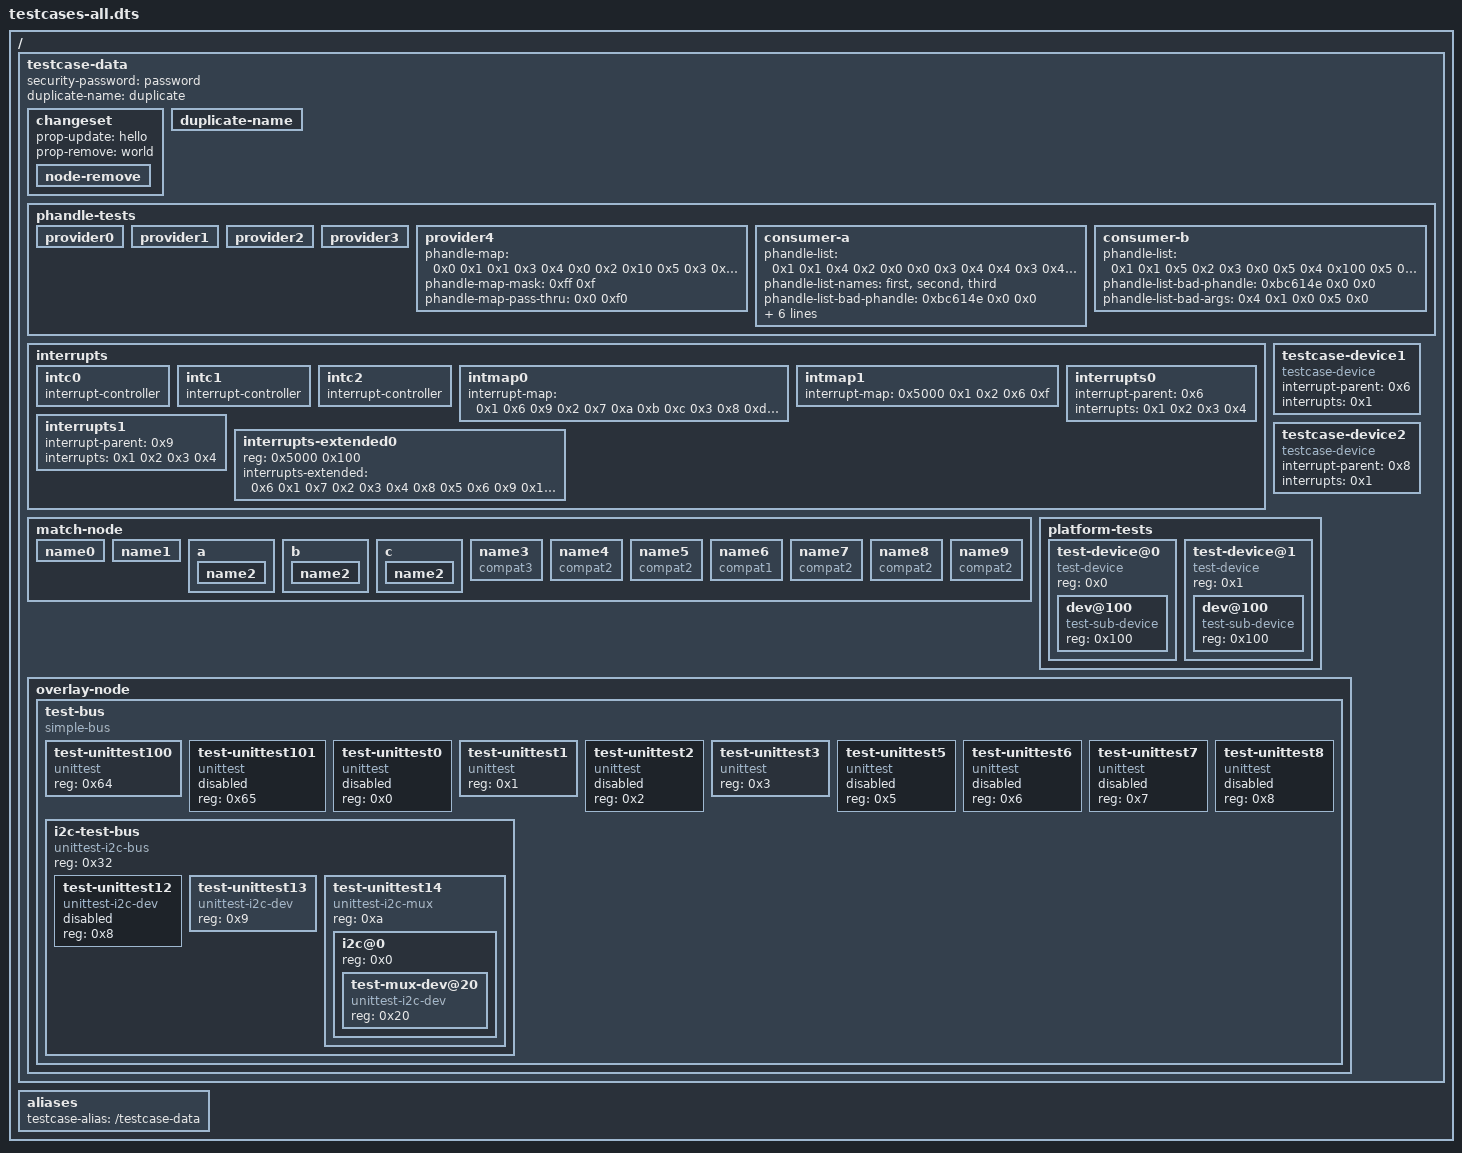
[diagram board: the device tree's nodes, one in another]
/dts-v1/;

/ {

	testcase-data {
		security-password = "password";
		duplicate-name = "duplicate";
		phandle = <0xb>;

		changeset {
			prop-update = "hello";
			prop-remove = "world";

			node-remove {
			};
		};

		duplicate-name {
		};

		phandle-tests {

			provider0 {
				#phandle-cells = <0x0>;
				phandle = <0x2>;
			};

			provider1 {
				#phandle-cells = <0x1>;
				phandle = <0x1>;
			};

			provider2 {
				#phandle-cells = <0x2>;
				phandle = <0x4>;
			};

			provider3 {
				#phandle-cells = <0x3>;
				phandle = <0x3>;
			};

			provider4 {
				#phandle-cells = <0x2>;
				phandle-map = <0x0 0x1 0x1 0x3 0x4 0x0 0x2 0x10 0x5 0x3 0x3 0x5 0x0 0xc8 0x8 0x4 0x17 0x6 0x13 0x0 0x4 0xf 0x0 0x2 0x3 0x3 0x2 0x5 0x3>;
				phandle-map-mask = <0xff 0xf>;
				phandle-map-pass-thru = <0x0 0xf0>;
				phandle = <0x5>;
			};

			consumer-a {
				phandle-list = <0x1 0x1 0x4 0x2 0x0 0x0 0x3 0x4 0x4 0x3 0x4 0x5 0x64 0x2 0x1 0x7>;
				phandle-list-names = "first", "second", "third";
				phandle-list-bad-phandle = <0xbc614e 0x0 0x0>;
				phandle-list-bad-args = <0x4 0x1 0x0 0x3 0x0>;
				empty-property;
				string-property = "foobar";
				unterminated-string = <0x40414243>;
				unterminated-string-list = [66 69 72 73 74 00 73 65 63 6f 6e 64 00 40 41 42 43];
			};

			consumer-b {
				phandle-list = <0x1 0x1 0x5 0x2 0x3 0x0 0x5 0x4 0x100 0x5 0x0 0x61 0x2 0x5 0x13 0x20>;
				phandle-list-bad-phandle = <0xbc614e 0x0 0x0>;
				phandle-list-bad-args = <0x4 0x1 0x0 0x5 0x0>;
			};
		};

		interrupts {
			#address-cells = <0x1>;
			#size-cells = <0x1>;

			intc0 {
				interrupt-controller;
				#interrupt-cells = <0x1>;
				phandle = <0x6>;
			};

			intc1 {
				interrupt-controller;
				#interrupt-cells = <0x3>;
				phandle = <0x7>;
			};

			intc2 {
				interrupt-controller;
				#interrupt-cells = <0x2>;
				phandle = <0x8>;
			};

			intmap0 {
				#interrupt-cells = <0x1>;
				#address-cells = <0x0>;
				interrupt-map = <0x1 0x6 0x9 0x2 0x7 0xa 0xb 0xc 0x3 0x8 0xd 0xe 0x4 0x8 0xf 0x10>;
				phandle = <0x9>;
			};

			intmap1 {
				#interrupt-cells = <0x2>;
				interrupt-map = <0x5000 0x1 0x2 0x6 0xf>;
				phandle = <0xa>;
			};

			interrupts0 {
				interrupt-parent = <0x6>;
				interrupts = <0x1 0x2 0x3 0x4>;
			};

			interrupts1 {
				interrupt-parent = <0x9>;
				interrupts = <0x1 0x2 0x3 0x4>;
			};

			interrupts-extended0 {
				reg = <0x5000 0x100>;
				interrupts-extended = <0x6 0x1 0x7 0x2 0x3 0x4 0x8 0x5 0x6 0x9 0x1 0x9 0x2 0x9 0x3 0xa 0x1 0x2>;
			};
		};

		testcase-device1 {
			compatible = "testcase-device";
			interrupt-parent = <0x6>;
			interrupts = <0x1>;
		};

		testcase-device2 {
			compatible = "testcase-device";
			interrupt-parent = <0x8>;
			interrupts = <0x1>;
		};

		match-node {

			name0 {
			};

			name1 {
				device_type = "type1";
			};

			a {

				name2 {
					device_type = "type1";
				};
			};

			b {

				name2 {
				};
			};

			c {

				name2 {
					device_type = "type2";
				};
			};

			name3 {
				compatible = "compat3";
			};

			name4 {
				compatible = "compat2", "compat3";
			};

			name5 {
				compatible = "compat2", "compat3";
			};

			name6 {
				compatible = "compat1", "compat2", "compat3";
			};

			name7 {
				compatible = "compat2";
				device_type = "type1";
			};

			name8 {
				compatible = "compat2";
				device_type = "type1";
			};

			name9 {
				compatible = "compat2";
			};
		};

		platform-tests {
			#address-cells = <0x1>;
			#size-cells = <0x0>;

			test-device@0 {
				compatible = "test-device";
				reg = <0x0>;
				#address-cells = <0x1>;
				#size-cells = <0x0>;

				dev@100 {
					compatible = "test-sub-device";
					reg = <0x100>;
				};
			};

			test-device@1 {
				compatible = "test-device";
				reg = <0x1>;
				#address-cells = <0x1>;
				#size-cells = <0x0>;

				dev@100 {
					compatible = "test-sub-device", "test-compat2", "test-compat3";
					reg = <0x100>;
				};
			};
		};

		overlay-node {

			test-bus {
				compatible = "simple-bus";
				#address-cells = <0x1>;
				#size-cells = <0x0>;
				phandle = <0xc>;

				test-unittest100 {
					compatible = "unittest";
					status = "okay";
					reg = <0x64>;
					phandle = <0xd>;
				};

				test-unittest101 {
					compatible = "unittest";
					status = "disabled";
					reg = <0x65>;
					phandle = <0xe>;
				};

				test-unittest0 {
					compatible = "unittest";
					status = "disabled";
					reg = <0x0>;
					phandle = <0xf>;
				};

				test-unittest1 {
					compatible = "unittest";
					status = "okay";
					reg = <0x1>;
					phandle = <0x10>;
				};

				test-unittest2 {
					compatible = "unittest";
					status = "disabled";
					reg = <0x2>;
					phandle = <0x11>;
				};

				test-unittest3 {
					compatible = "unittest";
					status = "okay";
					reg = <0x3>;
					phandle = <0x12>;
				};

				test-unittest5 {
					compatible = "unittest";
					status = "disabled";
					reg = <0x5>;
					phandle = <0x13>;
				};

				test-unittest6 {
					compatible = "unittest";
					status = "disabled";
					reg = <0x6>;
					phandle = <0x14>;
				};

				test-unittest7 {
					compatible = "unittest";
					status = "disabled";
					reg = <0x7>;
					phandle = <0x15>;
				};

				test-unittest8 {
					compatible = "unittest";
					status = "disabled";
					reg = <0x8>;
					phandle = <0x16>;
				};

				i2c-test-bus {
					compatible = "unittest-i2c-bus";
					status = "okay";
					reg = <0x32>;
					#address-cells = <0x1>;
					#size-cells = <0x0>;
					phandle = <0x17>;

					test-unittest12 {
						reg = <0x8>;
						compatible = "unittest-i2c-dev";
						status = "disabled";
					};

					test-unittest13 {
						reg = <0x9>;
						compatible = "unittest-i2c-dev";
						status = "okay";
					};

					test-unittest14 {
						reg = <0xa>;
						compatible = "unittest-i2c-mux";
						status = "okay";
						#address-cells = <0x1>;
						#size-cells = <0x0>;

						i2c@0 {
							#address-cells = <0x1>;
							#size-cells = <0x0>;
							reg = <0x0>;

							test-mux-dev@20 {
								reg = <0x20>;
								compatible = "unittest-i2c-dev";
								status = "okay";
							};
						};
					};
				};
			};
		};
	};

	aliases {
		testcase-alias = "/testcase-data";
	};

	__symbols__ {
		testcase = "/testcase-data";
		provider0 = "/testcase-data/phandle-tests/provider0";
		provider1 = "/testcase-data/phandle-tests/provider1";
		provider2 = "/testcase-data/phandle-tests/provider2";
		provider3 = "/testcase-data/phandle-tests/provider3";
		provider4 = "/testcase-data/phandle-tests/provider4";
		test_intc0 = "/testcase-data/interrupts/intc0";
		test_intc1 = "/testcase-data/interrupts/intc1";
		test_intc2 = "/testcase-data/interrupts/intc2";
		test_intmap0 = "/testcase-data/interrupts/intmap0";
		test_intmap1 = "/testcase-data/interrupts/intmap1";
		unittest_test_bus = "/testcase-data/overlay-node/test-bus";
		unittest100 = "/testcase-data/overlay-node/test-bus/test-unittest100";
		unittest101 = "/testcase-data/overlay-node/test-bus/test-unittest101";
		unittest0 = "/testcase-data/overlay-node/test-bus/test-unittest0";
		unittest1 = "/testcase-data/overlay-node/test-bus/test-unittest1";
		unittest2 = "/testcase-data/overlay-node/test-bus/test-unittest2";
		unittest3 = "/testcase-data/overlay-node/test-bus/test-unittest3";
		unittest5 = "/testcase-data/overlay-node/test-bus/test-unittest5";
		unittest6 = "/testcase-data/overlay-node/test-bus/test-unittest6";
		unittest7 = "/testcase-data/overlay-node/test-bus/test-unittest7";
		unittest8 = "/testcase-data/overlay-node/test-bus/test-unittest8";
		unittest_i2c_test_bus = "/testcase-data/overlay-node/test-bus/i2c-test-bus";
	};

	__local_fixups__ {

		testcase-data {

			phandle-tests {

				provider4 {
					phandle-map = <0x8 0x18 0x24 0x3c 0x50 0x64>;
				};

				consumer-a {
					phandle-list = <0x0 0x8 0x18 0x28 0x34 0x38>;
					phandle-list-bad-args = <0x0 0xc>;
				};

				consumer-b {
					phandle-list = <0x0 0x8 0x18 0x24 0x30 0x34>;
					phandle-list-bad-args = <0x0 0xc>;
				};
			};

			interrupts {

				intmap0 {
					interrupt-map = <0x4 0x10 0x24 0x34>;
				};

				intmap1 {
					interrupt-map = <0xc>;
				};

				interrupts0 {
					interrupt-parent = <0x0>;
				};

				interrupts1 {
					interrupt-parent = <0x0>;
				};

				interrupts-extended0 {
					interrupts-extended = <0x0 0x8 0x18 0x24 0x2c 0x34 0x3c>;
				};
			};

			testcase-device1 {
				interrupt-parent = <0x0>;
			};

			testcase-device2 {
				interrupt-parent = <0x0>;
			};
		};
	};
};
